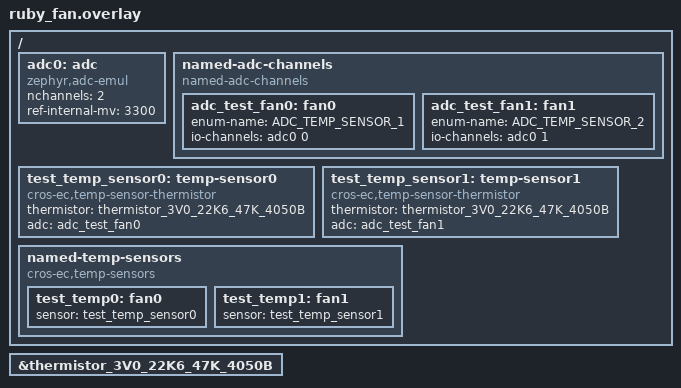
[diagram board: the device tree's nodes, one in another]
/* Copyright 2026 The ChromiumOS Authors
 * Use of this source code is governed by a BSD-style license that can be
 * found in the LICENSE file.
 */

#include <cros/thermistor/thermistor.dtsi>

&thermistor_3V0_22K6_47K_4050B {
	status = "okay";
};

/ {
	adc0: adc {
		compatible = "zephyr,adc-emul";
		nchannels = <2>;
		ref-internal-mv = <3300>;
		#io-channel-cells = <1>;
		status = "okay";
	};

	named-adc-channels {
		compatible = "named-adc-channels";

		adc_test_fan0: fan0 {
			enum-name = "ADC_TEMP_SENSOR_1";
			io-channels = <&adc0 0>;
		};
		adc_test_fan1: fan1 {
			enum-name = "ADC_TEMP_SENSOR_2";
			io-channels = <&adc0 1>;
		};
	};

	test_temp_sensor0: temp-sensor0 {
		compatible = "cros-ec,temp-sensor-thermistor";
		thermistor = <&thermistor_3V0_22K6_47K_4050B>;
		adc = <&adc_test_fan0>;
	};
	test_temp_sensor1: temp-sensor1 {
		compatible = "cros-ec,temp-sensor-thermistor";
		thermistor = <&thermistor_3V0_22K6_47K_4050B>;
		adc = <&adc_test_fan1>;
	};

	named-temp-sensors {
		compatible = "cros-ec,temp-sensors";

		test_temp0: fan0 {
			status = "okay";
			sensor = <&test_temp_sensor0>;
		};
		test_temp1: fan1 {
			status = "okay";
			sensor = <&test_temp_sensor1>;
		};
	};
};
